# PIC32MZ1064DAG169 device description
Architecture: MIPS; Family: PIC32MZDA; Series: PIC32MZ
Registers are 32-bit, read-write, no defined reset value unless marked. A register's access mark holds for its fields unless they carry their own. Offsets are from the block's base; [hi:lo] are bit positions; {n}, {i} and the like mark numbered series.

## CTMU
Instances: CTMU 0x1f84c200 in periph_pb3_std
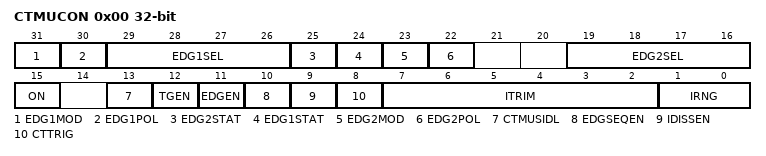
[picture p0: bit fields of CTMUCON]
0x00 CTMUCON — CTMU Control Register
  [31] EDG1MOD — Edge1 Edge Sampling Select bit
    1=Input is edge-sensitive; 0=Input is level-sensitive
  [30] EDG1POL — Edge 1 Polarity Select bit
    1=Edge1 programmed for a positive edge response; 0=Edge1 programmed for a negative edge response
  [29:26] EDG1SEL — Edge 1 Source Select bits
    14=C2OUT pin is selected; 13=C1OUT pin is selected; {v}=IC{v-6} Capture Event is selected (v=7..12); 6=OC4 Capture Event is selected; 5=OC3 Capture Event is selected; 4=OC2 Capture Event is selected; 3=CTED1 pin is selected; 2=CTED2 pin is selected; 1=OC1 Compare Event is selected; 0=Timer1 Event is selected
  [25] EDG2STAT — Edge2 Status bit
    1=Edge2 has occurred; 0=Edge2 has not occurred
  [24] EDG1STAT — Edge1 Status bit
    1=Edge1 has occurred; 0=Edge1 has not occurred
  [23] EDG2MOD — Edge2 Edge Sampling Select bit
    1=Input is edge-sensitive; 0=Input is level-sensitive
  [22] EDG2POL — Edge 2 Polarity Select bit
    1=Edge2 programmed for a positive edge response; 0=Edge2 programmed for a negative edge response
  [19:16] EDG2SEL — Edge 2 Source Select bits
    56=C2OUT pin is selected; 52=C1OUT pin is selected; 48=PBCLK3; 44=IC5 Capture Event is selected; 40=IC4 Capture Event is selected; 36=IC3 Capture Event is selected; 32=IC2 Capture Event is selected; 28=IC1 Capture Event is selected; 24=OC4 Capture Event is selected; 20=OC3 Capture Event is selected; 16=OC2 Capture Event is selected; 12=CTED1 pin is selected; 8=CTED2 pin is selected; 4=OC1 Compare Event is selected; 0=Timer1 Event is selected
  [15] ON — ON Enable bit
    1=Module is enabled; 0=Module is disabled
  [13] CTMUSIDL — Stop-in-Idle Mode bit
    1=Discontinue module operation when device enters Idle mode; 0=Continue module operation in Idle mode
  [12] TGEN — Time Generation Enable bit
    1=Enables edge delay generation; 0=Disables edge delay generation
  [11] EDGEN — Edge Enable bit
    1=Edges are not blocked; 0=Edges are blocked
  [10] EDGSEQEN — Edge Sequence Enable bit
    1=Edge1 must occur before Edge2 can occur; 0=No edge sequence is needed
  [9] IDISSEN — Analog Current Source Control bit
    1=Analog current source output is grounded; 0=Analog current source output is not grounded
  [8] CTTRIG — Trigger Control bit
    1=Trigger output is enabled; 0=Trigger output is disabled
  [7:2] ITRIM — Current Source Trim bits
    31=Maximum positive change from nominal current; 1=Minimum positive change from nominal current; 0=Nominal current output specified by IRNG; 63=Minimum negative change from nominal current; 33=Maximum negative change from nominal current
  [1:0] IRNG — Current Range Select bits
    3=100 times base current; 2=10 times base current; 1=Base current level; 0=1000 times base current(4)

## CVR
Instances: CVR 0x1f800e00 in periph_pb1_std
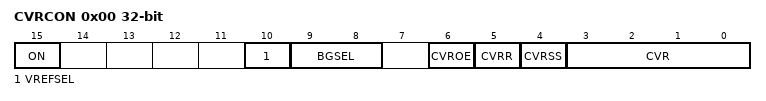
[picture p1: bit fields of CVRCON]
0x00 CVRCON — Comparator Voltage Reference Control Register
  [15] ON — Comparator Voltage Reference On bit
    1=Module is enabled. Setting this bit does not affect other bits in the register.; 0=Module is disabled and does not consume current. Clearing this bit does not affect the other bits in the register.
  [10] VREFSEL
  [9:8] BGSEL
  [6] CVROE — CVrefout Enable bit
    1=Voltage level is output on CVrefout pin; 0=Voltage level is disconnected from CVrefout pin
  [5] CVRR — CVref Range Selection bit
    1=0 to 0.67 CVrsrc; 0=0.25 CVrsrc to 0.75 CVrsrc
  [4] CVRSS — CVref Source Selection bit
    1=Comparator voltage reference source, CVRSRC = (VREF+) - (VREF-); 0=Comparator voltage reference source, CVRSRC = AVDD - AVSS
  [3:0] CVR

## DMT
Instances: DMT 0x1f800a00 in periph_pb1_std
0x00 DMTCON — Deadman Timer Control Register
  [15] ON — Deadman Timer Module Enable bit
    1=Deadman Timer module is enabled; 0=Deadman Timer module is disabled
0x10 DMTPRECLR — Deadman Timer Preclear Register
  [15:8] STEP1 — Preclear Enable bits
    64=Enables the Deadman Timer Preclear (Step 1)
0x20 DMTCLR — Deadman Timer Clear Register
  [7:0] STEP2 — Clear Timer bits
    8=Clears STEP1
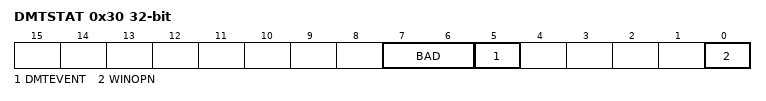
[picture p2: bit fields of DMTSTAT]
0x30 DMTSTAT ro — Deadman Timer Status Register
  [7:6] BAD
  [5] DMTEVENT — Deadman Timer Event bit
    1=Deadman timer event was detected (counter expired or bad STEP1 or STEP2 value was entered prior to counter increment); 0=Deadman timer even was not detected
  [0] WINOPN — Deadman Timer Clear Window bit
    1=Deadman timer clear window is open; 0=Deadman timer clear window is not open
0x40 DMTCNT ro — Deadman Timer Count Register
  [31:0] COUNTER
0x60 DMTPSCNT ro — Post Status Configure DMT Count Status Register
  [31:0] PSCNT
0x70 DMTPSINTV ro — Post Status Configure DMT Interval Status Register
  [31:0] PSINTV
Value list DMTSTAT__BAD2: 64=Incorrect STEP2 value was detected; 0=Incorrect STEP2 value was not detected
Value list DMTSTAT__BAD1: 128=Incorrect STEP1 value or out of sequence write to STEP2 was detected; 0=Incorrect STEP1 value was not detected

## Notices in the file
Copyright (c) 2017 Microchip Technology Inc.
SPDX-License-Identifier: Apache-2.0
Licensed under the Apache License, Version 2.0 (the "License");
you may not use this file except in compliance with the License.
You may obtain a copy of the License at
http://www.apache.org/licenses/LICENSE-2.0
Unless required by applicable law or agreed to in writing, software
distributed under the License is distributed on an "AS IS" BASIS,
WITHOUT WARRANTIES OR CONDITIONS OF ANY KIND, either express or implied.
See the License for the specific language governing permissions and
limitations under the License.
